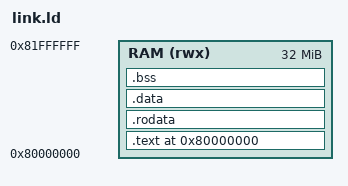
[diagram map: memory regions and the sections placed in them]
/* RV32 link script for the integrated boot image, QEMU 'virt', run in place. */

OUTPUT_ARCH("riscv")
OUTPUT_FORMAT("elf32-littleriscv")
ENTRY(_start)

MEMORY
{
    RAM (rwx) : ORIGIN = 0x80000000, LENGTH = 32M
}

STACK_SIZE = 256K;

SECTIONS
{
    . = ORIGIN(RAM);

    .text : {
        KEEP(*(.text.init))
        *(.text .text.*)
    } > RAM

    .rodata : {
        *(.rodata .rodata.*)
        *(.srodata .srodata.*)
    } > RAM

    .data : {
        *(.data .data.*)
        *(.sdata .sdata.*)
    } > RAM

    .bss (NOLOAD) : {
        . = ALIGN(16);
        _bss_start = .;
        *(.sbss .sbss.*)
        *(.bss .bss.*)
        *(COMMON)
        . = ALIGN(16);
        _bss_end = .;
    } > RAM

    . = ALIGN(16);
    . = . + STACK_SIZE;
    _stack_top = .;

    /DISCARD/ : { *(.comment) *(.note .note.*) *(.eh_frame) }
}
